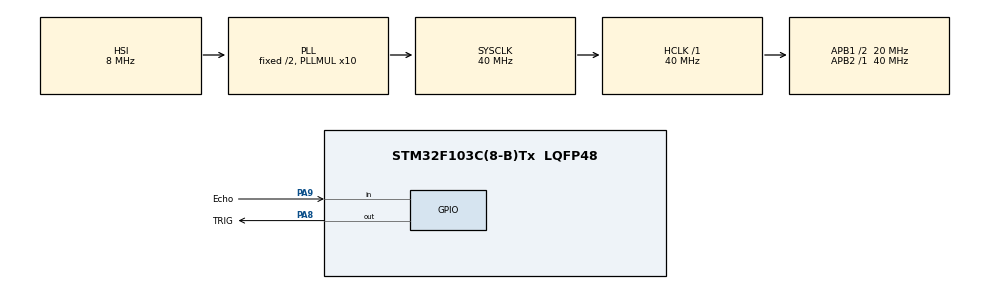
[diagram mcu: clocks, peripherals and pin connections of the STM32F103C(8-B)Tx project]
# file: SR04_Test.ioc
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Mcu.Family=STM32F1
Mcu.Name=STM32F103C(8-B)Tx
Mcu.Package=LQFP48
NVIC.PriorityGroup=NVIC_PRIORITYGROUP_4
PA13.Mode=Serial_Wire
PA13.Signal=SYS_JTMS-SWDIO
PA14.Mode=Serial_Wire
PA14.Signal=SYS_JTCK-SWCLK
PA8.GPIO_Label=TRIG
PA8.Signal=GPIO_Output
PA9.GPIO_Label=Echo
PA9.Signal=GPIO_Input
ProjectManager.HeapSize=0x200
ProjectManager.StackSize=0x400
ProjectManager.TargetToolchain=MDK-ARM V5.32
RCC.AHBFreq_Value=40000000
RCC.APB1CLKDivider=RCC_HCLK_DIV2
RCC.APB1Freq_Value=20000000
RCC.APB1TimFreq_Value=40000000
RCC.APB2Freq_Value=40000000
RCC.APB2TimFreq_Value=40000000
RCC.HCLKFreq_Value=40000000
RCC.PLLMUL=RCC_PLL_MUL10
RCC.SYSCLKFreq_VALUE=40000000
RCC.SYSCLKSource=RCC_SYSCLKSOURCE_PLLCLK
RCC.USBFreq_Value=40000000
TIM1.Period=0xffff-1
TIM1.Prescaler=40
TIM4.Period=0
TIM4.Prescaler=40-1
VP_TIM1_VS_ClockSourceINT.Mode=Internal
VP_TIM4_VS_ClockSourceINT.Mode=Internal
board=custom

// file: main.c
/* USER CODE BEGIN Header */
/**
  ******************************************************************************
  * @file           : main.c
  * @brief          : Main program body
  ******************************************************************************
  * @attention
  *
  * Copyright (c) 2023 STMicroelectronics.
  * All rights reserved.
  *
  * This software is licensed under terms that can be found in the LICENSE file
  * in the root directory of this software component.
  * If no LICENSE file comes with this software, it is provided AS-IS.
  *
  ******************************************************************************
  */
/* USER CODE END Header */
#include "main.h"
#include "tim.h"
#include "gpio.h"

/* USER CODE BEGIN PTD */
#define usTIM TIM4
/* USER CODE END PTD */

/* USER CODE BEGIN PV */
uint32_t  Tick_a =0;
uint32_t numticks = 0;
uint32_t Clock_Sys =0;
uint32_t Delayus = 0;
float clockt = 0.0 ;

/* USER CODE END PV */

void SystemClock_Config(void);
/* USER CODE BEGIN PFP */
void delay_us (uint16_t us);
void cal_distance (void);
/* USER CODE END PFP */

/* USER CODE BEGIN 0 */
// Speed of sound in cm
const float speedOfSound = 0.0343/2;
float distance;
//extern uint32_t  SYSCLKSource;

/* USER CODE END 0 */

int main(void)
{

  /* MCU Configuration--------------------------------------------------------*/

  /* Reset of all peripherals, Initializes the Flash interface and the Systick. */
  HAL_Init();

  /* Configure the system clock */
  SystemClock_Config();

  /* Initialize all configured peripherals */
  MX_GPIO_Init();
  MX_TIM4_Init();
  MX_TIM1_Init();
  /* USER CODE BEGIN 2 */
  HAL_TIM_Base_Start (&htim1);
  /* USER CODE END 2 */

  /* Infinite loop */
  while (1)
  {

    /* USER CODE BEGIN 3 */

      cal_distance();
      HAL_Delay(300);

     // clockt = RCC_ClkInitTypeDef;

      //Set TRIG to LOW for few usec

  }
  /* USER CODE END 3 */
}

void SystemClock_Config(void)
{
  RCC_OscInitTypeDef RCC_OscInitStruct = {0};
  RCC_ClkInitTypeDef RCC_ClkInitStruct = {0};

  /** Initializes the RCC Oscillators according to the specified parameters
  * in the RCC_OscInitTypeDef structure.
  */
  RCC_OscInitStruct.OscillatorType = RCC_OSCILLATORTYPE_HSI;
  RCC_OscInitStruct.HSIState = RCC_HSI_ON;
  RCC_OscInitStruct.HSICalibrationValue = RCC_HSICALIBRATION_DEFAULT;
  RCC_OscInitStruct.PLL.PLLState = RCC_PLL_ON;
  RCC_OscInitStruct.PLL.PLLSource = RCC_PLLSOURCE_HSI_DIV2;
  RCC_OscInitStruct.PLL.PLLMUL = RCC_PLL_MUL10;
  if (HAL_RCC_OscConfig(&RCC_OscInitStruct) != HAL_OK)
  {
    Error_Handler();
  }

  /** Initializes the CPU, AHB and APB buses clocks
  */
  RCC_ClkInitStruct.ClockType = RCC_CLOCKTYPE_HCLK|RCC_CLOCKTYPE_SYSCLK
                              |RCC_CLOCKTYPE_PCLK1|RCC_CLOCKTYPE_PCLK2;
  RCC_ClkInitStruct.SYSCLKSource = RCC_SYSCLKSOURCE_PLLCLK;
  RCC_ClkInitStruct.AHBCLKDivider = RCC_SYSCLK_DIV1;
  RCC_ClkInitStruct.APB1CLKDivider = RCC_HCLK_DIV2;
  RCC_ClkInitStruct.APB2CLKDivider = RCC_HCLK_DIV1;

  if (HAL_RCC_ClockConfig(&RCC_ClkInitStruct, FLASH_LATENCY_1) != HAL_OK)
  {
    Error_Handler();
  }
}

/* USER CODE BEGIN 4 */

void delay_us (uint16_t us)
{
    //HAL_TIM_SET_COUNTER(&htim1,0);  // set the counter value a 0
    //Delayus++;
    __HAL_TIM_SET_COUNTER(&htim1,0);

    while ((uint16_t)__HAL_TIM_GET_COUNTER(&htim1) < us);  // wait for the counter to reach the us input in the parameter

}

void cal_distance (void)
{
     HAL_GPIO_WritePin(GPIOA,GPIO_PIN_8,GPIO_PIN_RESET);
      delay_us(3);

      //***START**** ultrasonic measure routine ***//
      // 1. output 10 us TRIG
      HAL_GPIO_WritePin(GPIOA,GPIO_PIN_8,GPIO_PIN_SET);
      delay_us(10);
      HAL_GPIO_WritePin(GPIOA,GPIO_PIN_8,GPIO_PIN_RESET);

      //2.wait for ECHO pin is rising edge
      while(HAL_GPIO_ReadPin(GPIOA,GPIO_PIN_9)==GPIO_PIN_RESET);

      //3.start measure ECHO pulse width in uSec
      numticks = 0;
      while(HAL_GPIO_ReadPin(GPIOA,GPIO_PIN_9)==GPIO_PIN_SET)
      {
          numticks++;
          delay_us(2);   // 2.8 uSec
      };

      // estimate distance in cm
      distance = (numticks + 0.0f)*2.8*speedOfSound;

}
/* USER CODE END 4 */

void Error_Handler(void)
{
  __disable_irq();
  while (1)
  {
  }
}
